# STM32MP21_CM33 register map
File version: 0.4
CPU: CM33 r0p1, little endian, MPU, FPU, vendor SysTick, 8 interrupt priority bits
Registers are 32-bit, read-write, reset 0x0 unless marked. A register's access mark holds for its fields unless they carry their own. Offsets are from the block's base; [hi:lo] are bit positions; {n}, {i} and the like mark numbered series; 'fields as' and 'values as' point back to an identical list.

## TIM16 — TIM16 address block description
Base 0x40260000
Same registers: TIM16_S 0x50260000
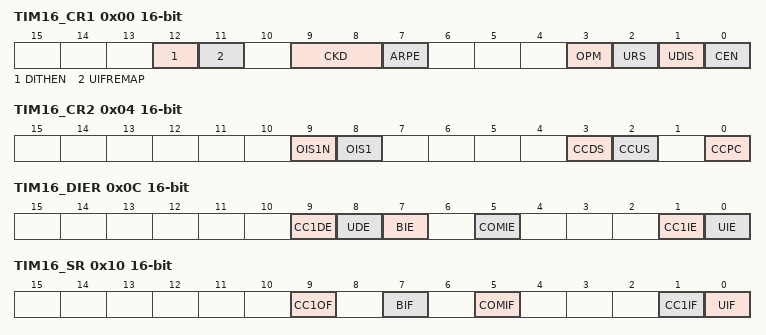
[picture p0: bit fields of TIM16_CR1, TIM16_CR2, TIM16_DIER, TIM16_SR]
0x00 TIM16_CR1 16-bit — TIM16 control register 1
  [12] DITHEN — Dithering enable
    0=Dithering disabled; 1=Dithering enabled
  [11] UIFREMAP — UIF status bit remapping
    0=No remapping; 1=Remapping enabled
  [9:8] CKD — Clock division
    0=tless thansub>DTSless than/sub>=tless thansub>tim_ker_ckless than/sub>; 1=tless thansub>DTSless than/sub>=2*tless thansub>tim_ker_ckless than/sub>; 2=tless thansub>DTSless than/sub>=4*tless thansub>tim_ker_ckless than/sub>
  [7] ARPE — Auto-reload preload enable
    0=TIMx_ARR register is not buffered; 1=TIMx_ARR register is buffered
  [3] OPM — One pulse mode
    0=Counter is not stopped at update event; 1=Counter stops counting at the next update event (clearing the bit CEN)
  [2] URS — Update request source
    0=Any of the following events generate an update interrupt or DMA request if enabled; 1=nly counter overflow/underflow generates an update interrupt or DMA request if enabled
  [1] UDIS — Update disable
    0=UEV enabled; 1=UEV disabled
  [0] CEN — Counter enable
    0=Counter disabled; 1=Counter enabled
0x04 TIM16_CR2 16-bit — TIM16 control register 2
  [9] OIS1N — Output Idle state 1 (tim_oc1n output)
    0=tim_oc1n=0 after a dead-time when MOE=0; 1=tim_oc1n=1 after a dead-time when MOE=0
  [8] OIS1 — Output Idle state 1 (tim_oc1 output)
    0=tim_oc1=0 after a dead-time when MOE=0; 1=tim_oc1=1 after a dead-time when MOE=0
  [3] CCDS — Capture/compare DMA selection
    0=CCx DMA request sent when CCx event occurs; 1=CCx DMA requests sent when update event occurs
  [2] CCUS — Capture/compare control update selection
    0=When capture/compare control bits are preloaded (CCPC=1), they are updated by setting the COMG bit only; 1=When capture/compare control bits are preloaded (CCPC=1), they are updated by setting the COMG bit or when a rising edge occurs on tim_trgi (if available)
  [0] CCPC — Capture/compare preloaded control
    0=CCxE, CCxNE and OCxM bits are not preloaded; 1=CCxE, CCxNE and OCxM bits are preloaded, after having been written, they are updated only when COM bit is set
0x0C TIM16_DIER 16-bit — TIM16 DMA/interrupt enable register
  [9] CC1DE — Capture/Compare 1 DMA request enable
    0=CC1 DMA request disabled; 1=CC1 DMA request enabled
  [8] UDE — Update DMA request enable
    0=Update DMA request disabled; 1=Update DMA request enabled
  [7] BIE — Break interrupt enable
    0=Break interrupt disabled; 1=Break interrupt enabled
  [5] COMIE — COM interrupt enable
    0=COM interrupt disabled; 1=COM interrupt enabled
  [1] CC1IE — Capture/Compare 1 interrupt enable
    0=CC1 interrupt disabled; 1=CC1 interrupt enabled
  [0] UIE — Update interrupt enable
    0=Update interrupt disabled; 1=Update interrupt enabled
0x10 TIM16_SR 16-bit — TIM16 status register
  [9] CC1OF — Capture/Compare 1 overcapture flag
    0=No overcapture has been detected; 1=The counter value has been captured in TIMx_CCR1 register while CC1IF flag was already set
  [7] BIF — Break interrupt flag
    0=No break event occurred; 1=An active level has been detected on the break input
  [5] COMIF — COM interrupt flag
    0=No COM event occurred; 1=COM interrupt pending
  [1] CC1IF — Capture/Compare 1 interrupt flag
    0=No compare match / No input capture occurred; 1=A compare match or an input capture occurred
  [0] UIF — Update interrupt flag
    0=No update occurred; 1=Update interrupt pending
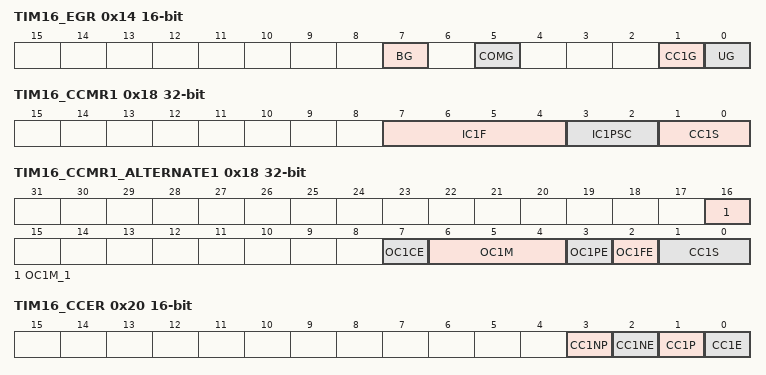
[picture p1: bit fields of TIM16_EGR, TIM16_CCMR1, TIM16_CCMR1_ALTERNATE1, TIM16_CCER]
0x14 TIM16_EGR 16-bit wo — TIM16 event generation register
  [7] BG — Break generation
    0=No action; 1=A break event is generated
  [5] COMG — Capture/Compare control update generation
    0=No action; 1=When the CCPC bit is set, it is possible to update the CCxE, CCxNE and OCxM bits
  [1] CC1G — Capture/Compare 1 generation
    0=No action; 1=A capture/compare event is generated on channel 1:
  [0] UG — Update generation
    0=No action; 1=Reinitialize the counter and generates an update of the registers
0x18 TIM16_CCMR1 — TIM16 capture/compare mode register 1
  [7:4] IC1F — Input capture 1 filter
    0=No filter, sampling is done at fless thansub>DTSless than/sub>; 1=fless thansub>SAMPLINGless than/sub>=fless thansub>tim_ker_ckless than/sub>, N=2; 2=fless thansub>SAMPLINGless than/sub>=fless thansub>tim_ker_ckless than/sub>, N=4; 3=fless thansub>SAMPLINGless than/sub>=fless thansub>tim_ker_ckless than/sub>, N=8; 4=fless thansub>SAMPLINGless than/sub>=fless thansub>DTSless than/sub>/2, N=; 5=fless thansub>SAMPLINGless than/sub>=fless thansub>DTSless than/sub>/2, N=8; 6=fless thansub>SAMPLINGless than/sub>=fless thansub>DTSless than/sub>/4, N=6; 7=fless thansub>SAMPLINGless than/sub>=fless thansub>DTSless than/sub>/4, N=8; 8=fless thansub>SAMPLINGless than/sub>=fless thansub>DTSless than/sub>/8, N=6; 9=fless thansub>SAMPLINGless than/sub>=fless thansub>DTSless than/sub>/8, N=8; 10=fless thansub>SAMPLINGless than/sub>=fless thansub>DTSless than/sub>/16, N=5; 11=fless thansub>SAMPLINGless than/sub>=fless thansub>DTSless than/sub>/16, N=6; 12=fless thansub>SAMPLINGless than/sub>=fless thansub>DTSless than/sub>/16, N=8; 13=fless thansub>SAMPLINGless than/sub>=fless thansub>DTSless than/sub>/32, N=5; 14=fless thansub>SAMPLINGless than/sub>=fless thansub>DTSless than/sub>/32, N=6; 15=fless thansub>SAMPLINGless than/sub>=fless thansub>DTSless than/sub>/32, N=8
  [3:2] IC1PSC — Input capture 1 prescaler
    0=no prescaler, capture is done each time an edge is detected on the capture input; 1=capture is done once every 2 events; 2=capture is done once every 4 events; 3=capture is done once every 8 events
  [1:0] CC1S — Capture/Compare 1 selection
    0=CC1 channel is configured as output; 1=CC1 channel is configured as input, tim_ic1 is mapped on tim_ti1
0x18 TIM16_CCMR1_ALTERNATE1 (alternate view of TIM16_CCMR1) — TIM16 capture/compare mode register 1
  [16] OC1M_1 — OC1M[3]
  [7] OC1CE — Output Compare 1 clear enable
    0=tim_oc1ref is not affected by the tim_ocref_clr input; 1=tim_oc1ref is cleared as soon as a High level is detected on tim_ocref_clr input
  [6:4] OC1M — OC1M[2:0]: Output Compare 1 mode
    0=Frozen - The comparison between the output compare register TIMx_CCR1 and the counter TIMx_CNT has no effect on the outputs; 1=Set channel 1 to active level on match; 2=Set channel 1 to inactive level on match; 3=Toggle - tim_oc1ref toggles when TIMx_CNT=TIMx_CCR1; 4=Force inactive level - tim_oc1ref is forced low; 5=Force active level - tim_oc1ref is forced high; 6=PWM mode 1 - Channel 1 is active as long as TIMx_CNTless thanTIMx_CCR1 else inactive; 7=PWM mode 2 - Channel 1 is inactive as long as TIMx_CNTless thanTIMx_CCR1 else active
  [3] OC1PE — Output Compare 1 preload enable
    0=Preload register on TIMx_CCR1 disabled; 1=Preload register on TIMx_CCR1 enabled
  [2] OC1FE — Output Compare 1 fast enable
    0=CC1 behaves normally depending on counter and CCR1 values even when the trigger is ON; 1=An active edge on the trigger input acts like a compare match on CC1 output
  [1:0] CC1S — Capture/Compare 1 selection
    values as TIM16_CCMR1.CC1S
0x20 TIM16_CCER 16-bit — TIM16 capture/compare enable register
  [3] CC1NP — Capture/Compare 1 complementary output polarity
    0=tim_oc1n active high; 1=tim_oc1n active low
  [2] CC1NE — Capture/Compare 1 complementary output enable
    0=Off - tim_oc1n is not active; 1=On - tim_oc1n signal is output on the corresponding output pin depending on MOE, OSSI, OSSR, OIS1, OIS1N and CC1E bits
  [1] CC1P — Capture/Compare 1 output polarity
    0=OC1 active high (output mode) / Edge sensitivity selection (input mode, see below); 1=OC1 active low (output mode) / Edge sensitivity selection (input mode, see below)
  [0] CC1E — Capture/Compare 1 output enable
    0=Capture mode disabled / OC1 is not active (see below); 1=Capture mode enabled / OC1 signal is output on the corresponding output pin
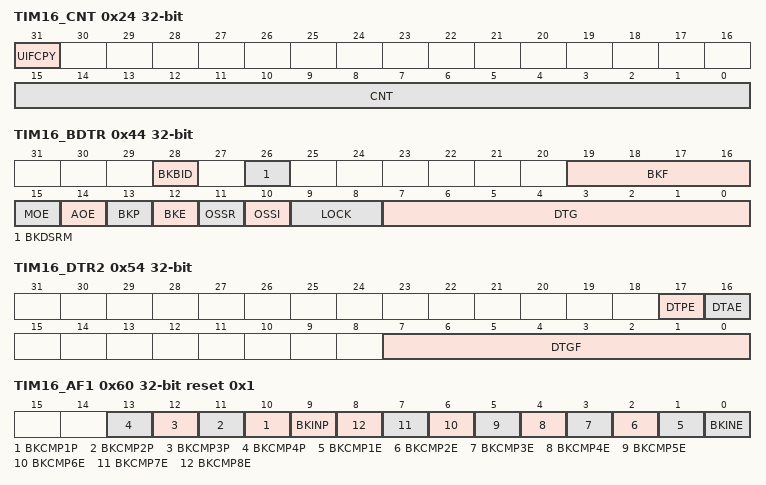
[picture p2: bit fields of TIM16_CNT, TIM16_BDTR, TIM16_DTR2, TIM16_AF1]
0x24 TIM16_CNT — TIM16 counter
  [31] UIFCPY ro — UIF Copy
  [15:0] CNT — Counter value
0x28 TIM16_PSC 16-bit — TIM16 prescaler
  [15:0] PSC — Prescaler value
0x2C TIM16_ARR reset 0xFFFF — TIM16 auto-reload register
  [19:0] ARR — Auto-reload value
0x30 TIM16_RCR 16-bit — TIM16 repetition counter register
  [7:0] REP — Repetition counter reload value
0x34 TIM16_CCR1 — TIM16 capture/compare register 1
  [19:0] CCR1 — Capture/Compare 1 value
0x44 TIM16_BDTR — TIM16 break and dead-time register
  [28] BKBID — Break Bidirectional
    0=Break input tim_brk in input mode; 1=Break input tim_brk in bidirectional mode
  [26] BKDSRM — Break Disarm
    0=Break input tim_brk is armed; 1=Break input tim_brk is disarmed
  [19:16] BKF — Break filter
    0=No filter, tim_brk acts asynchronously; 1=fless thansub>SAMPLINGless than/sub>=fless thansub>tim_ker_ckless than/sub>, N=2; 2=fless thansub>SAMPLINGless than/sub>=fless thansub>tim_ker_ckless than/sub>, N=4; 3=fless thansub>SAMPLINGless than/sub>=fless thansub>tim_ker_ckless than/sub>, N=8; 4=fless thansub>SAMPLINGless than/sub>=fless thansub>DTSless than/sub>/2, N=6; 5=fless thansub>SAMPLINGless than/sub>=fless thansub>DTSless than/sub>/2, N=8; 6=fless thansub>SAMPLINGless than/sub>=fless thansub>DTSless than/sub>/4, N=6; 7=fless thansub>SAMPLINGless than/sub>=fless thansub>DTSless than/sub>/4, N=8; 8=fless thansub>SAMPLINGless than/sub>=fless thansub>DTSless than/sub>/8, N=6; 9=fless thansub>SAMPLINGless than/sub>=fless thansub>DTSless than/sub>/8, N=8; 10=fless thansub>SAMPLINGless than/sub>=fless thansub>DTSless than/sub>/16, N=5; 11=fless thansub>SAMPLINGless than/sub>=fless thansub>DTSless than/sub>/16, N=6; 12=fless thansub>SAMPLINGless than/sub>=fless thansub>DTSless than/sub>/16, N=8; 13=fless thansub>SAMPLINGless than/sub>=fless thansub>DTSless than/sub>/32, N=5; 14=fless thansub>SAMPLINGless than/sub>=fless thansub>DTSless than/sub>/32, N=6; 15=fless thansub>SAMPLINGless than/sub>=fless thansub>DTSless than/sub>/32, N=8
  [15] MOE — Main output enable
    0=tim_oc1 and tim_oc1n outputs are disabled or forced to idle state depending on the OSSI bit; 1=tim_oc1 and tim_oc1n outputs are enabled if their respective enable bits are set (CC1E, CC1NE in TIMx_CCER register)
  [14] AOE — Automatic output enable
    0=MOE can be set only by software; 1=MOE can be set by software or automatically at the next update event (if the tim_brk input is not active)
  [13] BKP — Break polarity
    0=Break input tim_brk is active low; 1=Break input tim_brk is active high
  [12] BKE — Break enable
    0=Break inputs (tim_brk and tim_sys_brk event) disabled
  [11] OSSR — Off-state selection for Run mode
    0=When inactive, tim_oc1/tim_oc1n outputs are disabled (the timer releases the output control which is taken over by the GPIO, which forces a Hi-Z state); 1=When inactive, tim_oc1/tim_oc1n outputs are enabled with their inactive level as soon as CC1E=1 or CC1NE=1 (the output is still controlled by the timer)
  [10] OSSI — Off-state selection for Idle mode
    0=When inactive, tim_oc1/tim_oc1n outputs are disabled (tim_oc1/tim_oc1n enable output signal=0); 1=When inactive, tim_oc1/tim_oc1n outputs are forced first with their idle level as soon as CC1E=1 or CC1NE=1
  [9:8] LOCK — Lock configuration
    0=LOCK OFF - No bit is write protected; 1=LOCK Level 1 = DTG bits in TIMx_BDTR register, OISx and OISxN bits in TIMx_CR2 register and BKBID/BKE/BKP/AOE bits in TIMx_BDTR register can no longer be written; 2=LOCK Level 2 = LOCK Level 1 + CC Polarity bits (CCxP/CCxNP bits in TIMx_CCER register, as long as the related channel is configured in output through the CCxS bits) as well as OSSR and OSSI bits can no longer be written; 3=LOCK Level 3 = LOCK Level 2 + CC Control bits (OCxM and OCxPE bits in TIMx_CCMRx registers, as long as the related channel is configured in output through the CCxS bits) can no longer be written
  [7:0] DTG — Dead-time generator setup
0x54 TIM16_DTR2 — TIM16 timer deadtime register 2
  [17] DTPE — Deadtime preload enable
    0=Deadtime value is not preloaded; 1=Deadtime value preload is enabled
  [16] DTAE — Deadtime asymmetric enable
    0=Deadtime on rising and falling edges are identical, and defined with DTG[7:0] register; 1=Deadtime on rising edge is defined with DTG[7:0] register and deadtime on falling edge is defined with DTGF[7:0] bits
  [7:0] DTGF — Dead-time falling edge generator setup
0x5C TIM16_TISEL — TIM16 input selection register
  [3:0] TI1SEL — selects tim_ti1_in[15:0] input
    0=TIMx_CH1 input (tim_ti1_in0); 1=tim_ti1_in1; 15=tim_ti1_in15
0x60 TIM16_AF1 reset 0x1 — TIM16 alternate function register 1
  [n+9] BKCMP{n}P (n=1..4) — tim_brk_cmp{n} input polarity
    0=tim_brk_cmp{n} input is active high; 1=tim_brk_cmp{n} input is active low
  [9] BKINP — TIMx_BKIN input polarity
    0=TIMx_BKIN input is active high; 1=TIMx_BKIN input is active low
  [n] BKCMP{n}E (n=1..8) — tim_brk_cmp{n} enable
    0=tim_brk_cmp{n} input disabled; 1=tim_brk_cmp{n} input enabled
  [0] BKINE — TIMx_BKIN input enable
    0=TIMx_BKIN input disabled; 1=TIMx_BKIN input enabled
0x64 TIM16_AF2 — TIM16 alternate function register 2
  [18:16] OCRSEL — tim_ocref_clr source selection
    {v}=tim_ocref_clr{v} (v=0..7)
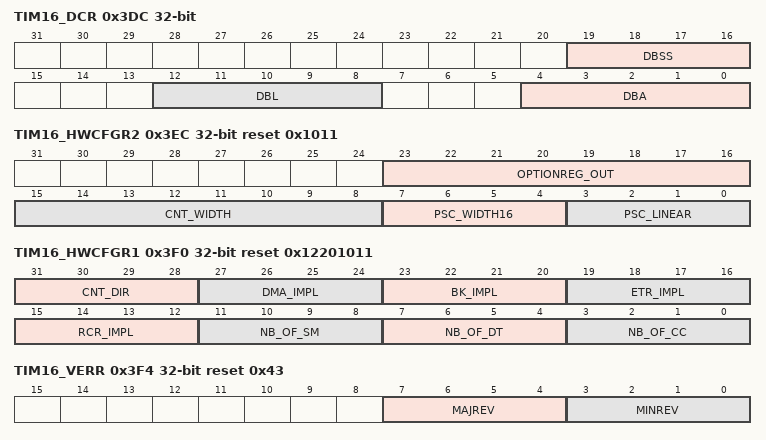
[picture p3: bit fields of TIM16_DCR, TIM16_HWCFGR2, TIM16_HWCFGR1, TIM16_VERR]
0x3DC TIM16_DCR — TIM16 DMA control register
  [19:16] DBSS — DMA burst source selection
    1=Update; 2=CC1
  [12:8] DBL — DMA burst length
    0=1 transfer,; 1=2 transfers,; 2=3 transfers,; 17=18 transfers
  [4:0] DBA — DMA base address
    0=TIMx_CR1,; 1=TIMx_CR2,; 2=TIMx_SMCR,
0x3E0 TIM16_DMAR — TIM16/TIM17 DMA address for full transfer
  [31:0] DMAB — DMA register for burst accesses
0x3EC TIM16_HWCFGR2 ro reset 0x1011 — TIM16 hardware configuration 2 register
  [23:16] OPTIONREG_OUT — Option register number (0 to 16).
  [15:8] CNT_WIDTH — Counter width
    8=8-bits; 16=16-bits; 32=32-bits
  [7:4] PSC_WIDTH16 — Prescaler width
    0=7 (by power of 2) /8 (linear) -bit counter; 1=15 (by power of 2) /16 (linear) -bit counter
  [3:0] PSC_LINEAR — Prescaler linear
    0=prescaler by power of 2 (division by 1, 2, 4, 8; 1=prescaler is linear (division by 1, 2, 3, 4, 5
0x3F0 TIM16_HWCFGR1 ro reset 0x12201011 — TIM16 hardware configuration 1 register
  [31:28] CNT_DIR — Counter direction
    0=Down-counter only; 1=Up-counter only; 2=Up/Down counter allowing center-aligned mode
  [27:24] DMA_IMPL — DMA features implementation
    0=DMA requests are not possible; 1=Single DMA requests possible; 2=All DMA features implemented
  [23:20] BK_IMPL — Break circuit implementation
    0=no break implemented; 1=break1 implemented without filter (tim_brk + tim_sys_brk connected); 2=break1 implemented with filter (tim_brk + tim_sys_brk connected); 3=break 1 and 2 implemented (tim_brk + tim_sys_brk + brk2)
  [19:16] ETR_IMPL — External trigger implementation
    0=External trigger circuit not implemented, ocrefx cleared by ocref_clr input; 1=External trigger circuit implemented, ocrefx cleared by ocref_clr input; 2=External trigger circuit implemented, ocrefx cleared by etrf signal; 3=External trigger circuit implemented, ocrefx cleared by ocref_clr or etrf (1 control bit OCCS added in GPT_SMCR)
  [15:12] RCR_IMPL — Repetition counter implementation
    0=repetition counter not implemented; 1=8-bit repetition counter implemented; 2=16-bit repetition counter implemented
  [11:8] NB_OF_SM — Number of synchronization module
    0=synchronization module not implemented; 1=1 synchronization module implemented
  [7:4] NB_OF_DT — Number of complementary outputs and dead-time generators
  [3:0] NB_OF_CC — Number of capture / compare channel
    0=no capture/compare channel implemented; 1=only CC1 channel is implemented; 2=CC1 and CC2 channels are implemented; 3=CC1, CC2 and CC3 channels are implemented; 4=CC1, CC2, CC3 and CC4 channels are implemented; 5=CC1, CC2, CC3, CC4 and CC5 channels are implemented; 6=CC1, CC2, CC3, CC4, CC5 and CC6 channels are implemented
0x3F4 TIM16_VERR ro reset 0x43 — TIM16 IP version register
  [7:4] MAJREV — Major revision number.
  [3:0] MINREV — Minor revision number.
0x3F8 TIM16_IPIDR ro reset 0x120002 — TIM16 IP identification register
  [31:0] ID — IP identification code.
0x3FC TIM16_SIDR ro reset 0xA3C5DD01 — TIM16 size ID register
  [31:0] SID — Offset in KB of the ID register base address from the IP base address.
    1=1KB offset

## TIM17 — TIM17 address block description
Base 0x40270000
Same registers: TIM17_S 0x50270000
Registers as TIM16 (with TIM16 read as TIM17); these are added or differ:
0x3E0 TIM17_DMAR — TIM16/TIM17 DMA address for full transfer
  [31:0] DMAB — DMA register for burst accesses
